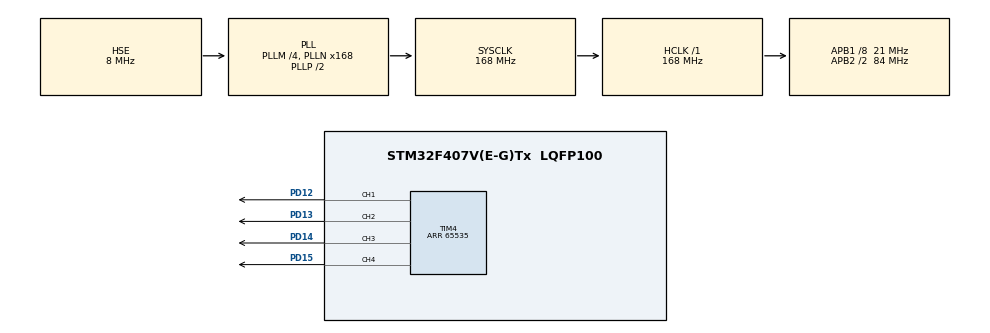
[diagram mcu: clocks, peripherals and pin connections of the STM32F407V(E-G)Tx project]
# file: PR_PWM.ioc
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Mcu.Family=STM32F4
Mcu.Name=STM32F407V(E-G)Tx
Mcu.Package=LQFP100
NVIC.PriorityGroup=NVIC_PRIORITYGROUP_0
NVIC.TIM4_IRQn=true\:0\:0\:false\:false\:true\:true
PD12.GPIO_Speed=GPIO_SPEED_FREQ_HIGH
PD12.Signal=S_TIM4_CH1
PD13.GPIO_Speed=GPIO_SPEED_FREQ_HIGH
PD13.Signal=S_TIM4_CH2
PD14.GPIO_Speed=GPIO_SPEED_FREQ_HIGH
PD14.Signal=S_TIM4_CH3
PD15.GPIO_Speed=GPIO_SPEED_FREQ_HIGH
PD15.Signal=S_TIM4_CH4
PH0-OSC_IN.Mode=HSE-External-Oscillator
PH0-OSC_IN.Signal=RCC_OSC_IN
PH1-OSC_OUT.Mode=HSE-External-Oscillator
PH1-OSC_OUT.Signal=RCC_OSC_OUT
ProjectManager.HeapSize=0x200
ProjectManager.StackSize=0x400
ProjectManager.TargetToolchain=MDK-ARM V5
RCC.48MHZClocksFreq_Value=48000000
RCC.AHBFreq_Value=168000000
RCC.APB1CLKDivider=RCC_HCLK_DIV8
RCC.APB1Freq_Value=21000000
RCC.APB1TimFreq_Value=42000000
RCC.APB2CLKDivider=RCC_HCLK_DIV2
RCC.APB2Freq_Value=84000000
RCC.APB2TimFreq_Value=168000000
RCC.CortexFreq_Value=168000000
RCC.HCLKFreq_Value=168000000
RCC.HSE_VALUE=8000000
RCC.HSI_VALUE=16000000
RCC.LSE_VALUE=32768
RCC.PLLM=4
RCC.PLLN=168
RCC.PLLQ=7
RCC.PLLSourceVirtual=RCC_PLLSOURCE_HSE
RCC.SYSCLKFreq_VALUE=168000000
RCC.SYSCLKSource=RCC_SYSCLKSOURCE_PLLCLK
RCC.VCOOutputFreq_Value=336000000
SH.S_TIM4_CH1.0=TIM4_CH1,PWM Generation1 CH1
SH.S_TIM4_CH2.0=TIM4_CH2,PWM Generation2 CH2
SH.S_TIM4_CH3.0=TIM4_CH3,PWM Generation3 CH3
SH.S_TIM4_CH4.0=TIM4_CH4,PWM Generation4 CH4
TIM4.Channel-PWM\ Generation1\ CH1=TIM_CHANNEL_1
TIM4.Channel-PWM\ Generation2\ CH2=TIM_CHANNEL_2
TIM4.Channel-PWM\ Generation3\ CH3=TIM_CHANNEL_3
TIM4.Channel-PWM\ Generation4\ CH4=TIM_CHANNEL_4
TIM4.Period=65535
VP_TIM4_VS_ClockSourceINT.Mode=Internal
board=STM32F4DISCOVERY

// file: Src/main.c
/**
  ******************************************************************************
  * @file           : main.c
  * @brief          : Main program body
  ******************************************************************************
  ** This notice applies to any and all portions of this file
  * that are not between comment pairs USER CODE BEGIN and
  * USER CODE END. Other portions of this file, whether
  * inserted by the user or by software development tools
  * are owned by their respective copyright owners.
  *
  * COPYRIGHT(c) 2018 STMicroelectronics
  *
  * Redistribution and use in source and binary forms, with or without modification,
  * are permitted provided that the following conditions are met:
  *   1. Redistributions of source code must retain the above copyright notice,
  *      this list of conditions and the following disclaimer.
  *   2. Redistributions in binary form must reproduce the above copyright notice,
  *      this list of conditions and the following disclaimer in the documentation
  *      and/or other materials provided with the distribution.
  *   3. Neither the name of STMicroelectronics nor the names of its contributors
  *      may be used to endorse or promote products derived from this software
  *      without specific prior written permission.
  *
  * THIS SOFTWARE IS PROVIDED BY THE COPYRIGHT HOLDERS AND CONTRIBUTORS "AS IS"
  * AND ANY EXPRESS OR IMPLIED WARRANTIES, INCLUDING, BUT NOT LIMITED TO, THE
  * IMPLIED WARRANTIES OF MERCHANTABILITY AND FITNESS FOR A PARTICULAR PURPOSE ARE
  * DISCLAIMED. IN NO EVENT SHALL THE COPYRIGHT HOLDER OR CONTRIBUTORS BE LIABLE
  * FOR ANY DIRECT, INDIRECT, INCIDENTAL, SPECIAL, EXEMPLARY, OR CONSEQUENTIAL
  * DAMAGES (INCLUDING, BUT NOT LIMITED TO, PROCUREMENT OF SUBSTITUTE GOODS OR
  * SERVICES; LOSS OF USE, DATA, OR PROFITS; OR BUSINESS INTERRUPTION) HOWEVER
  * CAUSED AND ON ANY THEORY OF LIABILITY, WHETHER IN CONTRACT, STRICT LIABILITY,
  * OR TORT (INCLUDING NEGLIGENCE OR OTHERWISE) ARISING IN ANY WAY OUT OF THE USE
  * OF THIS SOFTWARE, EVEN IF ADVISED OF THE POSSIBILITY OF SUCH DAMAGE.
  *
  ******************************************************************************
  */
#include "main.h"
#include "stm32f4xx_hal.h"

TIM_HandleTypeDef htim4;

/* USER CODE BEGIN PV */
/* Private variables ---------------------------------------------------------*/

/* USER CODE END PV */

void SystemClock_Config(void);
static void MX_GPIO_Init(void);
static void MX_TIM4_Init(void);
void HAL_TIM_MspPostInit(TIM_HandleTypeDef *htim);

/* USER CODE BEGIN PFP */
/* Private function prototypes -----------------------------------------------*/

/* USER CODE END PFP */

int main(void)
{

  /* MCU Configuration----------------------------------------------------------*/

  /* Reset of all peripherals, Initializes the Flash interface and the Systick. */
  HAL_Init();

  /* Configure the system clock */
  SystemClock_Config();

  /* Initialize all configured peripherals */
  MX_GPIO_Init();
  MX_TIM4_Init();
  /* USER CODE BEGIN 2 */
	HAL_TIM_PWM_Start(&htim4,TIM_CHANNEL_1);
	HAL_TIM_PWM_Start(&htim4,TIM_CHANNEL_2);
	HAL_TIM_PWM_Start(&htim4,TIM_CHANNEL_3);
	HAL_TIM_PWM_Start(&htim4,TIM_CHANNEL_4);
	uint32_t i,d;
  /* USER CODE END 2 */

  /* Infinite loop */
  /* USER CODE BEGIN WHILE */
  while (1)
  {
		TIM4->CCR1=60000;
		TIM4->CCR2=6000;
		TIM4->CCR3=1000;
		TIM4->CCR4=600;
//		for(i=0;i<524288;i++)
//		{
//			if(i<65536)        TIM4->CCR1=i;
//                        else if ((i>65535)&&(i<131072)) TIM4->CCR1=131071-i;
//                        else if((i>131071)&&(i<196608))        TIM4->CCR2=i-131072;
//                        else if ((i>196607)&&(i<262164)) TIM4->CCR2=262164-i;
//                        else if((i>262163)&&(i<327680))        TIM4->CCR3=i-262164;
//                        else if ((i>327679)&&(i<393216)) TIM4->CCR3=393216-i;
//                        else if((i>393216)&&(i<458752))        TIM4->CCR4=i-393216;
//                        else TIM4->CCR4=524288-i;
//                        for(d=0;d<300;d++)
//                        {
//
//                        }
//		}
  /* USER CODE END WHILE */

  }

}

void SystemClock_Config(void)
{

  RCC_OscInitTypeDef RCC_OscInitStruct;
  RCC_ClkInitTypeDef RCC_ClkInitStruct;

    /**Configure the main internal regulator output voltage
    */
  __HAL_RCC_PWR_CLK_ENABLE();

  __HAL_PWR_VOLTAGESCALING_CONFIG(PWR_REGULATOR_VOLTAGE_SCALE1);

    /**Initializes the CPU, AHB and APB busses clocks
    */
  RCC_OscInitStruct.OscillatorType = RCC_OSCILLATORTYPE_HSE;
  RCC_OscInitStruct.HSEState = RCC_HSE_ON;
  RCC_OscInitStruct.PLL.PLLState = RCC_PLL_ON;
  RCC_OscInitStruct.PLL.PLLSource = RCC_PLLSOURCE_HSE;
  RCC_OscInitStruct.PLL.PLLM = 4;
  RCC_OscInitStruct.PLL.PLLN = 168;
  RCC_OscInitStruct.PLL.PLLP = RCC_PLLP_DIV2;
  RCC_OscInitStruct.PLL.PLLQ = 7;
  if (HAL_RCC_OscConfig(&RCC_OscInitStruct) != HAL_OK)
  {
    _Error_Handler(__FILE__, __LINE__);
  }

    /**Initializes the CPU, AHB and APB busses clocks
    */
  RCC_ClkInitStruct.ClockType = RCC_CLOCKTYPE_HCLK|RCC_CLOCKTYPE_SYSCLK
                              |RCC_CLOCKTYPE_PCLK1|RCC_CLOCKTYPE_PCLK2;
  RCC_ClkInitStruct.SYSCLKSource = RCC_SYSCLKSOURCE_PLLCLK;
  RCC_ClkInitStruct.AHBCLKDivider = RCC_SYSCLK_DIV1;
  RCC_ClkInitStruct.APB1CLKDivider = RCC_HCLK_DIV8;
  RCC_ClkInitStruct.APB2CLKDivider = RCC_HCLK_DIV2;

  if (HAL_RCC_ClockConfig(&RCC_ClkInitStruct, FLASH_LATENCY_5) != HAL_OK)
  {
    _Error_Handler(__FILE__, __LINE__);
  }

    /**Configure the Systick interrupt time
    */
  HAL_SYSTICK_Config(HAL_RCC_GetHCLKFreq()/1000);

    /**Configure the Systick
    */
  HAL_SYSTICK_CLKSourceConfig(SYSTICK_CLKSOURCE_HCLK);

  /* SysTick_IRQn interrupt configuration */
  HAL_NVIC_SetPriority(SysTick_IRQn, 0, 0);
}

/* TIM4 init function */
static void MX_TIM4_Init(void)
{

  TIM_ClockConfigTypeDef sClockSourceConfig;
  TIM_MasterConfigTypeDef sMasterConfig;
  TIM_OC_InitTypeDef sConfigOC;

  htim4.Instance = TIM4;
  htim4.Init.Prescaler = 0;
  htim4.Init.CounterMode = TIM_COUNTERMODE_UP;
  htim4.Init.Period = 65535;
  htim4.Init.ClockDivision = TIM_CLOCKDIVISION_DIV1;
  if (HAL_TIM_Base_Init(&htim4) != HAL_OK)
  {
    _Error_Handler(__FILE__, __LINE__);
  }

  sClockSourceConfig.ClockSource = TIM_CLOCKSOURCE_INTERNAL;
  if (HAL_TIM_ConfigClockSource(&htim4, &sClockSourceConfig) != HAL_OK)
  {
    _Error_Handler(__FILE__, __LINE__);
  }

  if (HAL_TIM_PWM_Init(&htim4) != HAL_OK)
  {
    _Error_Handler(__FILE__, __LINE__);
  }

  sMasterConfig.MasterOutputTrigger = TIM_TRGO_RESET;
  sMasterConfig.MasterSlaveMode = TIM_MASTERSLAVEMODE_DISABLE;
  if (HAL_TIMEx_MasterConfigSynchronization(&htim4, &sMasterConfig) != HAL_OK)
  {
    _Error_Handler(__FILE__, __LINE__);
  }

  sConfigOC.OCMode = TIM_OCMODE_PWM1;
  sConfigOC.Pulse = 0;
  sConfigOC.OCPolarity = TIM_OCPOLARITY_HIGH;
  sConfigOC.OCFastMode = TIM_OCFAST_DISABLE;
  if (HAL_TIM_PWM_ConfigChannel(&htim4, &sConfigOC, TIM_CHANNEL_1) != HAL_OK)
  {
    _Error_Handler(__FILE__, __LINE__);
  }

  if (HAL_TIM_PWM_ConfigChannel(&htim4, &sConfigOC, TIM_CHANNEL_2) != HAL_OK)
  {
    _Error_Handler(__FILE__, __LINE__);
  }

  if (HAL_TIM_PWM_ConfigChannel(&htim4, &sConfigOC, TIM_CHANNEL_3) != HAL_OK)
  {
    _Error_Handler(__FILE__, __LINE__);
  }

  if (HAL_TIM_PWM_ConfigChannel(&htim4, &sConfigOC, TIM_CHANNEL_4) != HAL_OK)
  {
    _Error_Handler(__FILE__, __LINE__);
  }

  HAL_TIM_MspPostInit(&htim4);

}

/** Configure pins as
        * Analog
        * Input
        * Output
        * EVENT_OUT
        * EXTI
*/
static void MX_GPIO_Init(void)
{

  /* GPIO Ports Clock Enable */
  __HAL_RCC_GPIOH_CLK_ENABLE();
  __HAL_RCC_GPIOD_CLK_ENABLE();

}

void _Error_Handler(char *file, int line)
{
  while(1)
  {
  }
}

/************************ (C) COPYRIGHT STMicroelectronics *****END OF FILE****/
